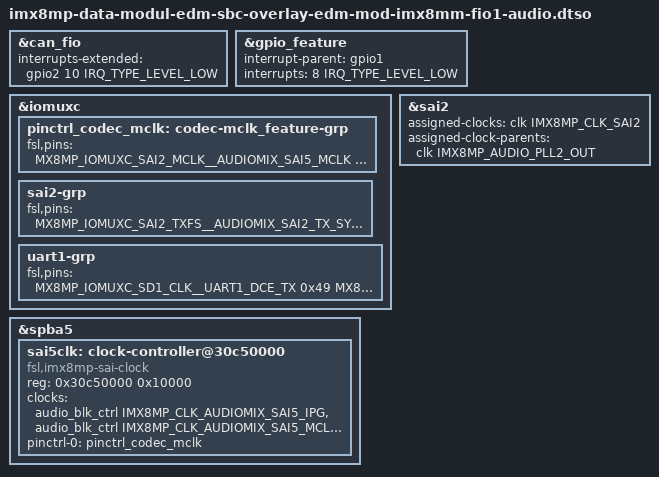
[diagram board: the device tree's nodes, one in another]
// SPDX-License-Identifier: (GPL-2.0+ OR MIT)
/*
 * Copyright 2024-2026 Marek Vasut
 */
/dts-v1/;
/plugin/;

#include <dt-bindings/clock/imx8mp-clock.h>

#include "imx8mp-pinfunc.h"
#include "imx8mm-data-modul-edm-sbc-overlay-edm-mod-imx8mm-fio1-audio.dtsi"

&can_fio {
	interrupts-extended = <&gpio2 10 IRQ_TYPE_LEVEL_LOW>;
};

&gpio_feature {
	interrupt-parent = <&gpio1>;
	interrupts = <8 IRQ_TYPE_LEVEL_LOW>;
};

&iomuxc {
	pinctrl_codec_mclk: codec-mclk_feature-grp {
		fsl,pins = <
			MX8MP_IOMUXC_SAI2_MCLK__AUDIOMIX_SAI5_MCLK	0xd6
		>;
	};

	sai2-grp {
		fsl,pins = <
			MX8MP_IOMUXC_SAI2_TXFS__AUDIOMIX_SAI2_TX_SYNC	0xd6
			MX8MP_IOMUXC_SAI2_TXD0__AUDIOMIX_SAI2_TX_DATA00	0xd6
			MX8MP_IOMUXC_SAI2_TXC__AUDIOMIX_SAI2_TX_BCLK	0xd6
			MX8MP_IOMUXC_SAI2_RXD0__AUDIOMIX_SAI2_RX_DATA00	0xd6
		>;
	};

	uart1-grp {
		fsl,pins = <
			MX8MP_IOMUXC_SD1_CLK__UART1_DCE_TX		0x49
			MX8MP_IOMUXC_SD1_CMD__UART1_DCE_RX		0x49
			MX8MP_IOMUXC_SD1_DATA1__UART1_DCE_CTS		0x49
		>;
	};
};

&sai2 {
	assigned-clocks = <&clk IMX8MP_CLK_SAI2>;
	assigned-clock-parents = <&clk IMX8MP_AUDIO_PLL2_OUT>;
};

&spba5 {
	#address-cells = <1>;
	#size-cells = <1>;

	sai5clk: clock-controller@30c50000 {
		compatible = "fsl,imx8mp-sai-clock", "fsl,imx8mq-sai-clock";
		reg = <0x30c50000 0x10000>;
		#clock-cells = <1>;
		clocks = <&audio_blk_ctrl IMX8MP_CLK_AUDIOMIX_SAI5_IPG>,
			 <&audio_blk_ctrl IMX8MP_CLK_AUDIOMIX_SAI5_MCLK1>;
		clock-names = "bus", "mclk1";
		pinctrl-names = "default";
		pinctrl-0 = <&pinctrl_codec_mclk>;
		status = "okay";
	};
};
